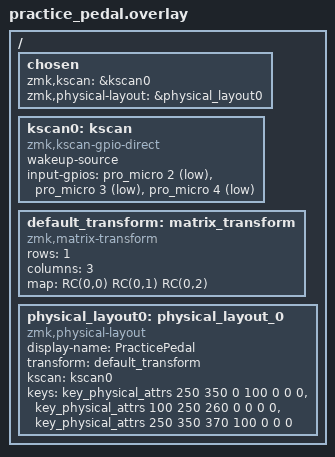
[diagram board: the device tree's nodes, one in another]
/*
 * PracticePedal: three switches, each wired from a nice!nano pin to GND.
 *
 *   key position 0  left pedal    D2  (P0.17)
 *   key position 1  centre key    D3  (P0.20)
 *   key position 2  right pedal   D4  (P0.22)
 */

#include <dt-bindings/zmk/matrix_transform.h>
#include <physical_layouts.dtsi>

/ {
    chosen {
        zmk,kscan = &kscan0;
        zmk,physical-layout = &physical_layout0;
    };

    kscan0: kscan {
        compatible = "zmk,kscan-gpio-direct";
        wakeup-source;
        input-gpios
            = <&pro_micro 2 (GPIO_ACTIVE_LOW | GPIO_PULL_UP)>
            , <&pro_micro 3 (GPIO_ACTIVE_LOW | GPIO_PULL_UP)>
            , <&pro_micro 4 (GPIO_ACTIVE_LOW | GPIO_PULL_UP)>
            ;
    };

    default_transform: matrix_transform {
        compatible = "zmk,matrix-transform";
        rows = <1>;
        columns = <3>;
        map = <RC(0,0) RC(0,1) RC(0,2)>;
    };

    physical_layout0: physical_layout_0 {
        compatible = "zmk,physical-layout";
        display-name = "PracticePedal";
        transform = <&default_transform>;
        kscan = <&kscan0>;
        keys  //                     w   h    x    y     rot    rx    ry
            = <&key_physical_attrs 250 350    0  100       0     0     0>
            , <&key_physical_attrs 100 250  260    0       0     0     0>
            , <&key_physical_attrs 250 350  370  100       0     0     0>
            ;
    };
};
